# STM32G414xx register map
File version: 1.0
Registers are 32-bit, read-write, reset 0x0 unless marked. A register's access mark holds for its fields unless they carry their own. Offsets are from the block's base; [hi:lo] are bit positions; lines under a group give offsets from that group; {n}, {i} and the like mark numbered series.

## ADC12_COMMON
Base 0x50000300
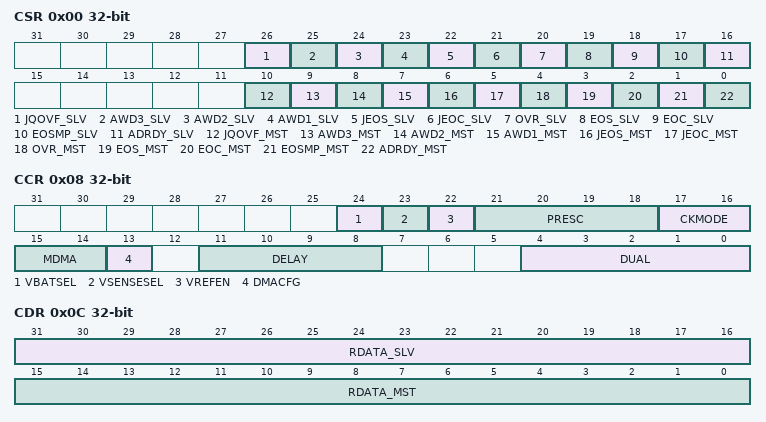
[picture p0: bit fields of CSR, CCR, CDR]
0x00 CSR — ADC common status register
  [26] JQOVF_SLV — ADC multimode slave group injected contexts queue overflow flag
  [25] AWD3_SLV — ADC multimode slave analog watchdog 3 flag
  [24] AWD2_SLV — ADC multimode slave analog watchdog 2 flag
  [23] AWD1_SLV — ADC multimode slave analog watchdog 1 flag
  [22] JEOS_SLV — ADC multimode slave group injected end of sequence conversions flag
  [21] JEOC_SLV — ADC multimode slave group injected end of unitary conversion flag
  [20] OVR_SLV — ADC multimode slave group regular overrun flag
  [19] EOS_SLV — ADC multimode slave group regular end of sequence conversions flag
  [18] EOC_SLV — ADC multimode slave group regular end of unitary conversion flag
  [17] EOSMP_SLV — ADC multimode slave group regular end of sampling flag
  [16] ADRDY_SLV — ADC multimode slave ready flag
  [10] JQOVF_MST — ADC multimode master group injected contexts queue overflow flag
  [9] AWD3_MST — ADC multimode master analog watchdog 3 flag
  [8] AWD2_MST — ADC multimode master analog watchdog 2 flag
  [7] AWD1_MST — ADC multimode master analog watchdog 1 flag
  [6] JEOS_MST — ADC multimode master group injected end of sequence conversions flag
  [5] JEOC_MST — ADC multimode master group injected end of unitary conversion flag
  [4] OVR_MST — ADC multimode master group regular overrun flag
  [3] EOS_MST — ADC multimode master group regular end of sequence conversions flag
  [2] EOC_MST — ADC multimode master group regular end of unitary conversion flag
  [1] EOSMP_MST — ADC multimode master group regular end of sampling flag
  [0] ADRDY_MST — ADC multimode master ready flag
0x08 CCR — ADC common configuration register
  [24] VBATSEL — ADC internal path to battery voltage enable
  [23] VSENSESEL — ADC internal path to temperature sensor enable
  [22] VREFEN — ADC internal path to VrefInt enable
  [21:18] PRESC — ADC common clock prescaler, only for clock source asynchronous
  [17:16] CKMODE — ADC common clock source and prescaler (prescaler only for clock source synchronous)
  [15:14] MDMA — ADC multimode DMA transfer enable
  [13] DMACFG — ADC multimode DMA transfer configuration
  [11:8] DELAY — ADC multimode delay between 2 sampling phases
    0=DELAY_1CYCLE; {v}=DELAY_{v+1}CYCLES (v=1..11)
  [4:0] DUAL — ADC multimode mode selection
    0=INDEPENDENT; 6=DUAL_REG_SIMULT; 7=DUAL_REG_INTERL; 5=DUAL_INJ_SIMULT; 9=DUAL_INJ_ALTERN; 1=DUAL_REG_SIM_INJ_SIM; 2=DUAL_REG_SIM_INJ_ALT; 3=DUAL_REG_INT_INJ_SIM
0x0C CDR — ADC common group regular data register
  [31:16] RDATA_SLV — ADC multimode slave group regular conversion data
  [15:0] RDATA_MST — ADC multimode master group regular conversion data

## AES — AES hardware accelerator
Base 0x50060000
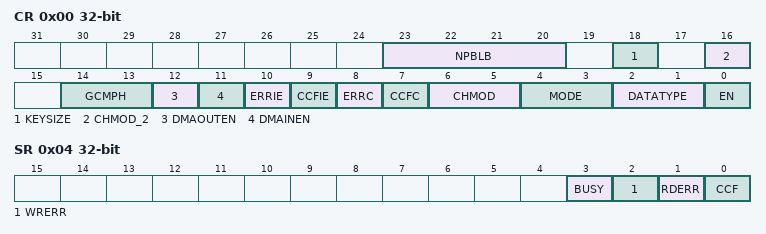
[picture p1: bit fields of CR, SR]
0x00 CR — AES control register
  [23:20] NPBLB — Number of padding bytes in payload last block
  [18] KEYSIZE — Key size selection
  [16] CHMOD_2 — AES Chaining Mode
  [14:13] GCMPH — GCM Phase
  [12] DMAOUTEN — Enable data output phase DMA management
  [11] DMAINEN — Enable data input phase DMA management
  [10] ERRIE — Error Interrupt Enable
  [9] CCFIE — Computation Complete Flag Interrupt Enable
  [8] ERRC — Error Clear
  [7] CCFC — Computation Complete Flag Clear
  [6:5] CHMOD — AES Chaining Mode
  [4:3] MODE — AES Mode Of Operation
  [2:1] DATATYPE — Data type selection
  [0] EN — AES Enable
0x04 SR — AES status register
  [3] BUSY — Busy Flag
  [2] WRERR — Write Error Flag
  [1] RDERR — Read Error Flag
  [0] CCF — Computation Complete Flag
0x08 DINR — AES data input register
  [31:0] DINR — AES Data Input Register
0x0C DOUTR — AES data output register
  [31:0] DOUTR — AES Data Output Register
{0x10+4i} KEYR{i} (i=0..3) — AES key register {i}
  [31:0] KEYR{i} — AES Key Register {i}
{0x20+4i} IVR{i} (i=0..3) — AES initialization vector register {i}
  [31:0] IVR{i} — AES Initialization Vector Register {i}
{0x20+4i} KEYR{i} (i=4..7) — AES key register {i}
  [31:0] KEYR{i} — AES Key Register {i}
{0x40+4i} SUSP{i}R (i=0..7) — AES Suspend register {i}
  [31:0] SUSP{i}R — AES Suspend registers {i}

## RNG
Base 0x50060800
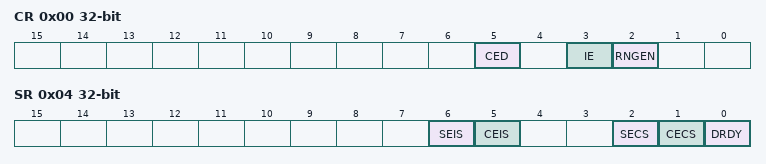
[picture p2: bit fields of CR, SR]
0x00 CR — RNG control register
  [5] CED, [3] IE, [2] RNGEN
0x04 SR — RNG status register
  [6] SEIS, [5] CEIS, [2] SECS, [1] CECS, [0] DRDY
0x08 DR — RNG data register

## DBGMCU — Debug MCU
Base 0xE0042000
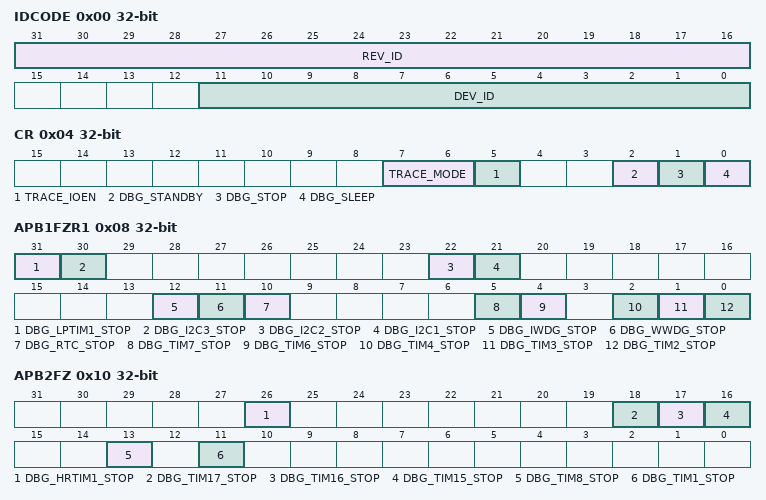
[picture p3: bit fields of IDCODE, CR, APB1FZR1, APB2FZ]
0x00 IDCODE — MCU device ID code
  [31:16] REV_ID, [11:0] DEV_ID
0x04 CR — Debug MCU configuration register
  [7:6] TRACE_MODE, [5] TRACE_IOEN, [2] DBG_STANDBY, [1] DBG_STOP, [0] DBG_SLEEP
0x08 APB1FZR1 — Debug MCU APB1 freeze register 1
  [31] DBG_LPTIM1_STOP, [30] DBG_I2C3_STOP, [22] DBG_I2C2_STOP, [21] DBG_I2C1_STOP, [12] DBG_IWDG_STOP, [11] DBG_WWDG_STOP, [10] DBG_RTC_STOP, [5] DBG_TIM7_STOP, [4] DBG_TIM6_STOP, [2] DBG_TIM4_STOP, [1] DBG_TIM3_STOP, [0] DBG_TIM2_STOP
0x0C APB1FZR2 — Debug MCU APB1 freeze register 2
0x10 APB2FZ — Debug MCU APB2 freeze register
  [26] DBG_HRTIM1_STOP, [18] DBG_TIM17_STOP, [17] DBG_TIM16_STOP, [16] DBG_TIM15_STOP, [13] DBG_TIM8_STOP, [11] DBG_TIM1_STOP
